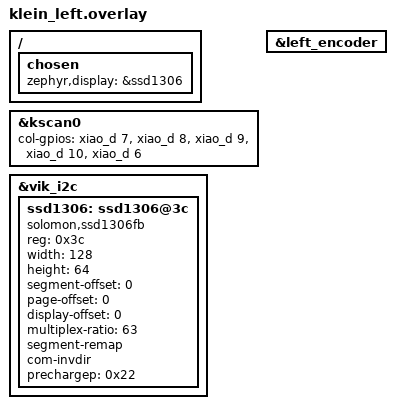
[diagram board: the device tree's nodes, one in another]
/*
 * Copyright (c) 2020 Derek Schmell
 *
 * SPDX-License-Identifier: MIT
 */

#include "klein.dtsi"

&kscan0 {
    col-gpios
        = <&xiao_d 7  (GPIO_ACTIVE_HIGH | GPIO_PULL_DOWN)>
        , <&xiao_d 8  (GPIO_ACTIVE_HIGH | GPIO_PULL_DOWN)>
        , <&xiao_d 9  (GPIO_ACTIVE_HIGH | GPIO_PULL_DOWN)>
        , <&xiao_d 10  (GPIO_ACTIVE_HIGH | GPIO_PULL_DOWN)>
        , <&xiao_d 6  (GPIO_ACTIVE_HIGH | GPIO_PULL_DOWN)>
        ;
};

/ {
	chosen {
		zephyr,display = &ssd1306;
	};
};

&vik_i2c {
	status = "okay";

	ssd1306: ssd1306@3c {
		compatible = "solomon,ssd1306fb";
		reg = <0x3c>;
		width = <128>;
		height = <64>;
		segment-offset = <0>;
		page-offset = <0>;
		display-offset = <0>;
		multiplex-ratio = <63>;
		segment-remap;
		com-invdir;
		prechargep = <0x22>;
	};
};

&left_encoder {
    status = "okay";
};

